CM_ "IMPORT _honda_common.dbc";
CM_ "IMPORT _nidec_common.dbc";
CM_ "IMPORT _nidec_scm_group_a.dbc";
CM_ "IMPORT _steering_sensors_b.dbc";
CM_ "IMPORT _steering_control_b.dbc";
CM_ "IMPORT _gearbox_common.dbc";

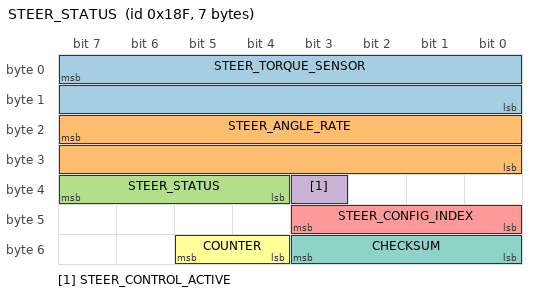
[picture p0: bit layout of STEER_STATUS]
BO_ 399 STEER_STATUS: 7 EPS
 SG_ STEER_TORQUE_SENSOR : 7|16@0- (-1,0) [-31000|31000] "tbd" EON
 SG_ STEER_ANGLE_RATE : 23|16@0- (-0.1,0) [-31000|31000] "deg/s" EON
 SG_ STEER_STATUS : 39|4@0+ (1,0) [0|15] "" EON
 SG_ STEER_CONTROL_ACTIVE : 35|1@0+ (1,0) [0|1] "" EON
 SG_ STEER_CONFIG_INDEX : 43|4@0+ (1,0) [0|15] "" EON
 SG_ COUNTER : 53|2@0+ (1,0) [0|3] "" EON
 SG_ CHECKSUM : 51|4@0+ (1,0) [0|3] "" EON

VAL_ 399 STEER_STATUS 7 "permanent_fault" 6 "tmp_fault" 5 "fault_1" 4 "no_torque_alert_2" 3 "low_speed_lockout" 2 "no_torque_alert_1" 0 "normal" ;
